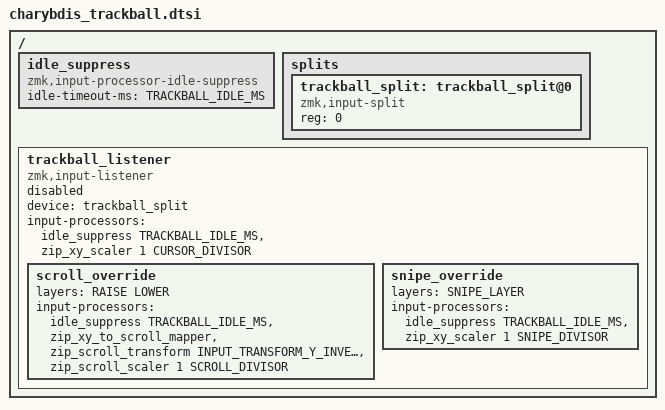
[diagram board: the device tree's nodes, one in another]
#include <input/processors.dtsi>
#include <zephyr/dt-bindings/input/input-event-codes.h>
#include <dt-bindings/zmk/input_transform.h>
#include "../../../charybdis_parameters.h"

/ {
    // Suppress trackball events while typing. Returns ZMK_INPUT_PROC_STOP
    // to completely drop events within TRACKBALL_IDLE_MS of last keypress.
    idle_suppress: idle_suppress {
        compatible = "zmk,input-processor-idle-suppress";
        #input-processor-cells = <1>;
        idle-timeout-ms = <TRACKBALL_IDLE_MS>;
    };

    // Split proxy — receives trackball events relayed from the right
    // peripheral over BLE and re-emits them on the central side.
    splits {
        #address-cells = <1>;
        #size-cells = <0>;
        trackball_split: trackball_split@0 {
            compatible = "zmk,input-split";
            reg = <0>;
        };
    };

    // Input listener — enabled only on the central (dongle) overlay.
    trackball_listener: trackball_listener {
        compatible = "zmk,input-listener";
        status = "disabled";
        device = <&trackball_split>;

        // Default: suppress during typing, then scale cursor
        input-processors = <&idle_suppress TRACKBALL_IDLE_MS &zip_xy_scaler 1 CURSOR_DIVISOR>;

        // RAISE / LOWER: convert movement to scroll events
        scroll_override: scroll_override {
            layers = <RAISE LOWER>;
            input-processors = <
                &idle_suppress TRACKBALL_IDLE_MS
                &zip_xy_to_scroll_mapper
                &zip_scroll_transform INPUT_TRANSFORM_Y_INVERT
                &zip_scroll_scaler 1 SCROLL_DIVISOR
            >;
        };

        // SNIPE_LAYER: precision cursor (slower movement)
        snipe_override: snipe_override {
            layers = <SNIPE_LAYER>;
            input-processors = <&idle_suppress TRACKBALL_IDLE_MS &zip_xy_scaler 1 SNIPE_DIVISOR>;
        };
    };
};
